# GD32F10x_XD register map
File version: 1.0
CPU: CM3 r2p1, little endian, no MPU, no FPU, 4 interrupt priority bits
Registers are 32-bit, read-write, reset 0x0 unless marked. A register's access mark holds for its fields unless they carry their own. Offsets are from the block's base; [hi:lo] are bit positions.

## TIMER5 — Basic-timers
Base 0x40001000
Same registers: TIMER6 0x40001400
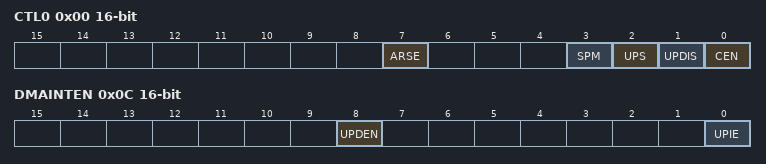
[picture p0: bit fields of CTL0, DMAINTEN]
0x00 CTL0 16-bit — control register 0
  [7] ARSE — Auto-reload shadow enable
  [3] SPM — Single pulse mode
  [2] UPS — Update source
  [1] UPDIS — Update disable
  [0] CEN — Counter enable
0x04 CTL1 16-bit — control register 1
  [6:4] MMC — Master mode control
0x0C DMAINTEN 16-bit — DMA/Interrupt enable register
  [8] UPDEN — Update DMA request enable
  [0] UPIE — Update interrupt enable
0x10 INTF 16-bit — Interrupt flag register
  [0] UPIF — Update interrupt flag
0x14 SWEVG 16-bit wo — event generation register
  [0] UPG — Update generation
0x24 CNT 16-bit — Counter register
  [15:0] CNT — Low counter value
0x28 PSC 16-bit — Prescaler register
  [15:0] PSC — Prescaler value of the counter clock
0x2C CAR 16-bit — Counter auto reload register
  [15:0] CARL — Counter auto reload value

## TIMER9 — General-purpose-timers
Base 0x40015000
Same registers: TIMER12 0x40001C00, TIMER13 0x40002000, TIMER10 0x40015400
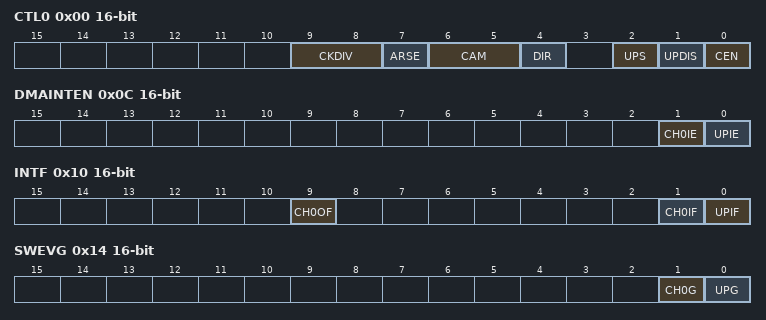
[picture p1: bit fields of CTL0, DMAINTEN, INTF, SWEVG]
0x00 CTL0 16-bit — control register 1
  [9:8] CKDIV — Clock division
  [7] ARSE — Auto-reload shadow enable
  [6:5] CAM — Counter aligns mode selection
  [4] DIR — Direction
  [2] UPS — Update source
  [1] UPDIS — Update disable
  [0] CEN — Counter enable
0x04 CTL1 16-bit — control register 1
  [6:4] MMC — Master mode control
0x0C DMAINTEN 16-bit — DMA/Interrupt enable register
  [1] CH0IE — Channel 0 capture/compare interrupt enable
  [0] UPIE — Update interrupt enable
0x10 INTF 16-bit — interrupt flag register
  [9] CH0OF — Channel 0 over capture flag
  [1] CH0IF — Channel 0 capture/compare interrupt flag
  [0] UPIF — Update interrupt flag
0x14 SWEVG 16-bit wo — event generation register
  [1] CH0G — Channel 0 capture or compare event generation
  [0] UPG — Update generation
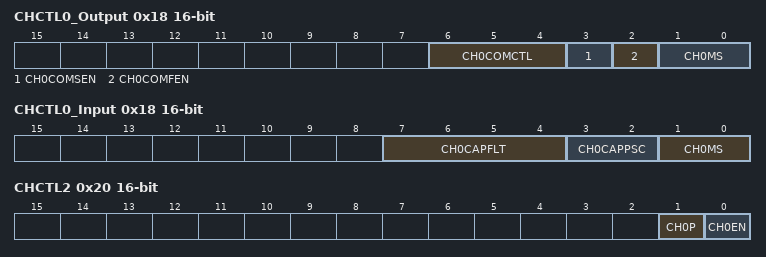
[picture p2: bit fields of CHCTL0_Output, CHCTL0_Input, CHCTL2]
0x18 CHCTL0_Output 16-bit — Channel control register 0 (output mode)
  [6:4] CH0COMCTL — Channel 0 compare output control
  [3] CH0COMSEN — Channel 0 compare output shadow enable
  [2] CH0COMFEN — Channel 0 output compare fast enable
  [1:0] CH0MS — Channel 0 I/O mode selection
0x18 CHCTL0_Input 16-bit (alternate view of CHCTL0_Output) — Channel control register 0 ( (input mode)
  [7:4] CH0CAPFLT — Channel 0 input capture filter control
  [3:2] CH0CAPPSC — Channel 0 input capture prescaler
  [1:0] CH0MS — Channel 0 mode selection
0x20 CHCTL2 16-bit — Channel control register 2
  [1] CH0P — Channel 0 capture/compare polarity
  [0] CH0EN — Channel 0 capture/compare function enable
0x24 CNT 16-bit — Counter register
  [15:0] CNT — current counter value
0x28 PSC 16-bit — Prescaler register
  [15:0] PSC — Prescaler value of the counter clock
0x2C CAR 16-bit — Counter auto reload register
  [15:0] CARL — Counter auto reload value
0x34 CH0CV 16-bit — Channel 0 capture/compare value register
  [15:0] CH0VAL — Capture or compare value of channel 0

## USART0 — Universal synchronous asynchronous receiver transmitter
Base 0x40013800
Same registers: USART1 0x40004400, USART2 0x40004800
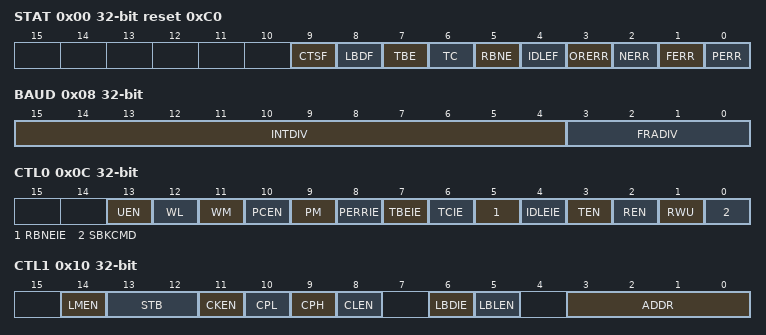
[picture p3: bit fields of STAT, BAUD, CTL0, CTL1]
0x00 STAT access per field reset 0xC0 — Status register
  [9] CTSF rw — CTS change flag
  [8] LBDF rw — LIN break detection flag
  [7] TBE ro — Transmit data buffer empty
  [6] TC rw — Transmission complete
  [5] RBNE rw — Read data buffer not empty
  [4] IDLEF ro — IDLE frame detected flag
  [3] ORERR ro — Overrun error
  [2] NERR ro — Noise error flag
  [1] FERR ro — Frame error flag
  [0] PERR ro — Parity error flag
0x04 DATA
  [8:0] DATA — Transmit or read data value
0x08 BAUD — Baud rate register
  [15:4] INTDIV — Integer part of baud-rate divider
  [3:0] FRADIV — Fraction part of baud-rate divider
0x0C CTL0 — Control register 0
  [13] UEN — USART enable
  [12] WL — Word length
  [11] WM — Wakeup method in mute mode
  [10] PCEN — Parity check function enable
  [9] PM — Parity mode
  [8] PERRIE — Parity error interrupt enable
  [7] TBEIE — Transmitter buffer empty interrupt enable
  [6] TCIE — Transmission complete interrupt enable
  [5] RBNEIE — Read data buffer not empty interrupt and overrun error interrupt enable
  [4] IDLEIE — IDLE line detected interrupt enable
  [3] TEN — Transmitter enable
  [2] REN — Receiver enable
  [1] RWU — Receiver wakeup from mute mode
  [0] SBKCMD — Send break command
0x10 CTL1 — Control register 1
  [14] LMEN — LIN mode enable
  [13:12] STB — STOP bits length
  [11] CKEN — CK pin enable
  [10] CPL — Clock polarity
  [9] CPH — Clock phase
  [8] CLEN — CK Length
  [6] LBDIE — LIN break detection interrupt enable
  [5] LBLEN — LIN break frame length
  [3:0] ADDR — Address of the USART
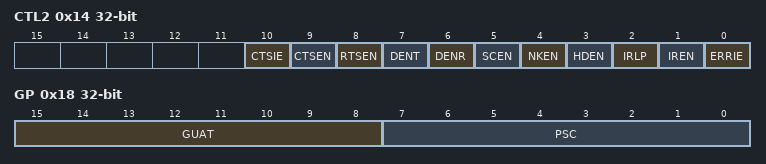
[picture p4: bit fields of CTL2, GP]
0x14 CTL2 — Control register 2
  [10] CTSIE — CTS interrupt enable
  [9] CTSEN — CTS enable
  [8] RTSEN — RTS enable
  [7] DENT — DMA request enable for transmission
  [6] DENR — DMA request enable for reception
  [5] SCEN — Smartcard mode enable
  [4] NKEN — Smartcard NACK enable
  [3] HDEN — Half-duplex selection
  [2] IRLP — IrDA low-power
  [1] IREN — IrDA mode enable
  [0] ERRIE — Error interrupt enable
0x18 GP — Guard time and prescaler register
  [15:8] GUAT — Guard time value in Smartcard mode
  [7:0] PSC — Prescaler value
